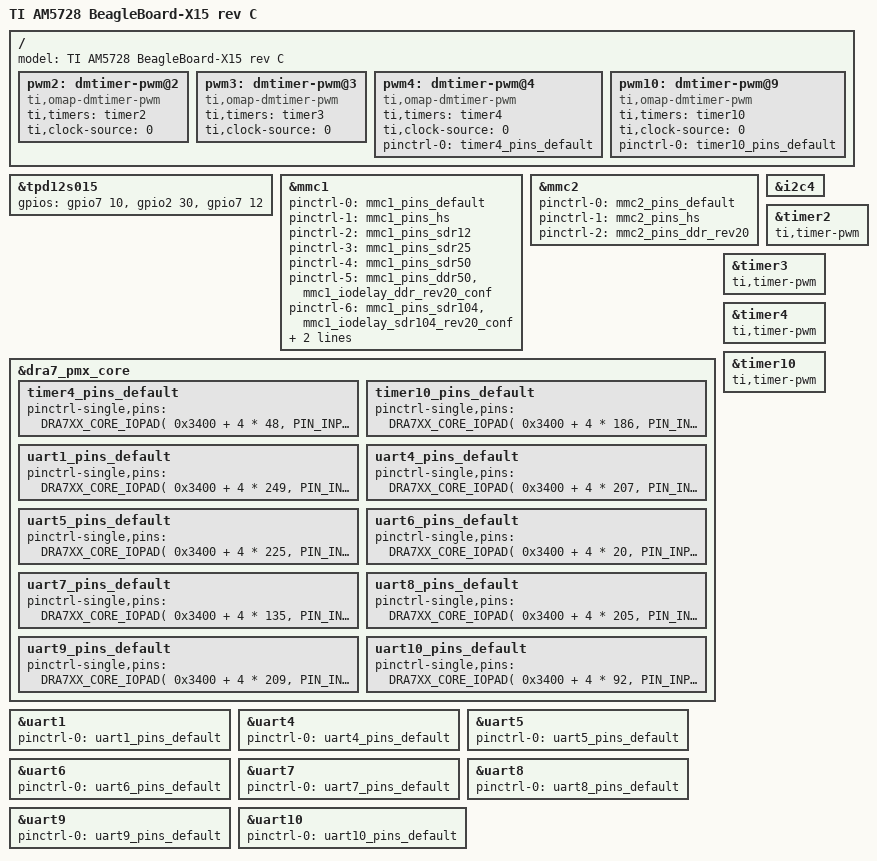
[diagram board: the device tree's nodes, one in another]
/*
 * Modify original am57xx-beagle-x15-revc.dts to allow use of
 * - I2C 4
 * - UARTs 1, 4, 5, 6, 7, 8, 9 and 10
 * - PWM (using timers 2, 3, 4 and 10)
 * and make them accessible via the bbx15 expansion headers
 *
 * Notes:
 * UARTs:
 * The debian stretch kernel only has six UARTs enabled by default, 
 * whereas this DTS enables nine (the eight above, plus existing UART3)
 * To make all of these UARTs available, change the following in the
 * kernel config and recompile the kernel:
 *   # anything >= 9 should be ok
 *   CONFIG_SERIAL_8250_NR_UARTS=12
 *   CONFIG_SERIAL_8250_RUNTIME_UARTS=12
 *
 * PWM:
 * Can be accessed via the sysfs interface (/sys/class/pwm/pwmchipx)
 * See the Kernel's Documentation/pwm.txt for details.
 */


//-----------------------------------------------------------------------------------------------------------
// original am57xx-beagle-x15-revc.dts
/*
 * Copyright (C) 2014-2017 Texas Instruments Incorporated - http://www.ti.com/
 *
 * This program is free software; you can redistribute it and/or modify
 * it under the terms of the GNU General Public License version 2 as
 * published by the Free Software Foundation.
 */

#include "am57xx-beagle-x15-common.dtsi"
#include "am57xx-cmem.dtsi"

/ {
	model = "TI AM5728 BeagleBoard-X15 rev C";

};

&tpd12s015 {
	gpios = <&gpio7 10 GPIO_ACTIVE_HIGH>,	/* gpio7_10, CT CP HPD */
		<&gpio2 30 GPIO_ACTIVE_HIGH>,	/* gpio2_30, LS OE */
		<&gpio7 12 GPIO_ACTIVE_HIGH>;	/* gpio7_12/sp1_cs2, HPD */
};

&mmc1 {
	pinctrl-names = "default", "hs", "sdr12", "sdr25", "sdr50", "ddr50", "sdr104";
	pinctrl-0 = <&mmc1_pins_default>;
	pinctrl-1 = <&mmc1_pins_hs>;
	pinctrl-2 = <&mmc1_pins_sdr12>;
	pinctrl-3 = <&mmc1_pins_sdr25>;
	pinctrl-4 = <&mmc1_pins_sdr50>;
	pinctrl-5 = <&mmc1_pins_ddr50 &mmc1_iodelay_ddr_rev20_conf>;
	pinctrl-6 = <&mmc1_pins_sdr104 &mmc1_iodelay_sdr104_rev20_conf>;
	vmmc-supply = <&vdd_3v3>;
	vqmmc-supply = <&ldo1_reg>;
};

&mmc2 {
	pinctrl-names = "default", "hs", "ddr_1_8v";
	pinctrl-0 = <&mmc2_pins_default>;
	pinctrl-1 = <&mmc2_pins_hs>;
	pinctrl-2 = <&mmc2_pins_ddr_rev20>;
};
//-----------------------------------------------------------------------------------------------------------
// end original am57xx-beagle-x15-revc.dts

/* set pinmux for extra IO */
&dra7_pmx_core {
//-----------------------------------------------------------------------------------------------------------
// pin mux for timers

  // already set by default
  //timer1_pins_default: timer1_pins_default {
  //  pinctrl-single,pins = <
  //    DRA7XX_CORE_IOPAD( 0x3400 + 4 * 162, PIN_INPUT_SLEW | MUX_MODE10 ) // E21 timer0    P17.42
  //  >;
  //}; 

  // already set by default
  //timer2_pins_default: timer2_pins_default {
  //  pinctrl-single,pins = <
  //    DRA7XX_CORE_IOPAD( 0x3400 + 4 * 163, PIN_INPUT_SLEW | MUX_MODE10 ) // F20 timer1    P17.13
  //  >;
  //}; 
		
  // already set by default
  //timer3_pins_default: timer3_pins_default {
  //  pinctrl-single,pins = <
  //    DRA7XX_CORE_IOPAD( 0x3400 + 4 * 164, PIN_INPUT_SLEW | MUX_MODE10 ) // F21 timer2    P17.12
  //  >;
  //}; 
		
  timer4_pins_default: timer4_pins_default {
    pinctrl-single,pins = <
      DRA7XX_CORE_IOPAD( 0x3400 + 4 * 48, PIN_INPUT_SLEW | MUX_MODE7 ) // P07 timer3        P16.35
    >;
  }; 

  timer10_pins_default: timer10_pins_default {
    pinctrl-single,pins = <
      DRA7XX_CORE_IOPAD( 0x3400 + 4 * 186, PIN_INPUT_SLEW | MUX_MODE10 ) // A13 timer9      P17.49
    >;
  };   

//-----------------------------------------------------------------------------------------------------------		
// pin mux for I2C

  // already set by default
  //i2c4_pins_default: i2c4_pins_default {
  //  pinctrl-single,pins = <
  //    DRA7XX_CORE_IOPAD( 0x3400 + 4 * 172, PIN_INPUT_SLEW | MUX_MODE10 ) // J14 i2c 3 scl [IO]  P17.46
  //    DRA7XX_CORE_IOPAD( 0x3400 + 4 * 171, PIN_INPUT_SLEW | MUX_MODE10 ) // B14 i2c 3 sda [IO]  P17.53
  //  >;
  //}; 

//-----------------------------------------------------------------------------------------------------------
// pin mux for uarts
  
  uart1_pins_default: uart1_pins_default {
    pinctrl-single,pins = <
      DRA7XX_CORE_IOPAD( 0x3400 + 4 * 249, PIN_INPUT_SLEW | MUX_MODE0 ) // B27 uart0 rxd    P18.30
      DRA7XX_CORE_IOPAD( 0x3400 + 4 * 248, PIN_INPUT_SLEW | MUX_MODE0 ) // C26 uart0 txd    P18.60
    >;
  };  
  
  // uart 2 not available (no pins available)
  
  // uart3 already set by default
  //uart3_pins_default: uart3_pins_default {
  //	pinctrl-single,pins = <
  //    DRA7XX_CORE_IOPAD( 0x3400 + 4 * 254, PIN_INPUT_SLEW | MUX_MODE2 ) // D27 uart2 rxd  P10.4
  //    DRA7XX_CORE_IOPAD( 0x3400 + 4 * 255, PIN_INPUT_SLEW | MUX_MODE1 ) // C28 uart2 txd  P10.5
  //	>;
  //};  

  uart4_pins_default: uart4_pins_default {
		pinctrl-single,pins = <
      DRA7XX_CORE_IOPAD( 0x3400 + 4 * 207, PIN_INPUT_SLEW | MUX_MODE4 ) // G16 uart3 rxd    P17.11
      DRA7XX_CORE_IOPAD( 0x3400 + 4 * 208, PIN_INPUT_SLEW | MUX_MODE4 ) // D17 uart3 txd    P17.14
		>;
	};

  uart5_pins_default: uart5_pins_default {
		pinctrl-single,pins = <
      DRA7XX_CORE_IOPAD( 0x3400 + 4 * 225, PIN_INPUT_SLEW | MUX_MODE2 ) // AC07 uart4 rxd   P17.7
      DRA7XX_CORE_IOPAD( 0x3400 + 4 * 226, PIN_INPUT_SLEW | MUX_MODE2 ) // AC06 uart4 txd   P17.36
		>;
	};   
  
  uart6_pins_default: uart6_pins_default {
    pinctrl-single,pins = <
      DRA7XX_CORE_IOPAD( 0x3400 + 4 * 20, PIN_INPUT_SLEW | MUX_MODE8 ) // P06 uart5 rxd     P16.10
      DRA7XX_CORE_IOPAD( 0x3400 + 4 * 21, PIN_INPUT_SLEW | MUX_MODE8 ) // R09 uart5 txd     P16.13
    >;
  };  
  
  uart7_pins_default: uart7_pins_default {
    pinctrl-single,pins = <
      DRA7XX_CORE_IOPAD( 0x3400 + 4 * 135, PIN_INPUT_SLEW | MUX_MODE2 ) // B07 uart6 rxd    P18.50
      DRA7XX_CORE_IOPAD( 0x3400 + 4 * 136, PIN_INPUT_SLEW | MUX_MODE2 ) // B08 uart6 txd    P18.51
    >;
  };   
  
  uart8_pins_default: uart8_pins_default {
    pinctrl-single,pins = <
      DRA7XX_CORE_IOPAD( 0x3400 + 4 * 205, PIN_INPUT_SLEW | MUX_MODE3 ) // C18 uart7 rxd    P17.43
      DRA7XX_CORE_IOPAD( 0x3400 + 4 * 206, PIN_INPUT_SLEW | MUX_MODE3 ) // A21 uart7 txd    P17.27
    >;
  };   

  uart9_pins_default: uart9_pins_default {
    pinctrl-single,pins = <
      DRA7XX_CORE_IOPAD( 0x3400 + 4 * 209, PIN_INPUT_SLEW | MUX_MODE3 ) // AA03 uart8 rxd   P17.10
      DRA7XX_CORE_IOPAD( 0x3400 + 4 * 210, PIN_INPUT_SLEW | MUX_MODE3 ) // AB09 uart8 txd   P17.9
    >;
  }; 
    
  uart10_pins_default: uart10_pins_default {
    pinctrl-single,pins = <
      DRA7XX_CORE_IOPAD( 0x3400 + 4 * 92, PIN_INPUT_SLEW | MUX_MODE8 ) // D01 uart9 rxd     P18.12
      DRA7XX_CORE_IOPAD( 0x3400 + 4 * 93, PIN_INPUT_SLEW | MUX_MODE8 ) // E02 uart9 txd     P18.42
    >;
  };
//-----------------------------------------------------------------------------------------------------------

};  // end pin-muxing

/* enable extra io */
&uart1 {
  pinctrl-names = "default";
  pinctrl-0 = <&uart1_pins_default>;  
	status = "okay";
};

&uart4 {
  pinctrl-names = "default";
  pinctrl-0 = <&uart4_pins_default>;    
	status = "okay";
};

&uart5 {
  pinctrl-names = "default";
  pinctrl-0 = <&uart5_pins_default>;  
	status = "okay";
};

&uart6 {
  pinctrl-names = "default";
  pinctrl-0 = <&uart6_pins_default>;    
	status = "okay";
};

&uart7 {
  pinctrl-names = "default";
  pinctrl-0 = <&uart7_pins_default>;    
	status = "okay";
};

&uart8 {
  pinctrl-names = "default";
  pinctrl-0 = <&uart8_pins_default>;    
	status = "okay";
};

&uart9 {
  pinctrl-names = "default";
  pinctrl-0 = <&uart9_pins_default>;  
	status = "okay";
};

&uart10 {
  pinctrl-names = "default";
  pinctrl-0 = <&uart10_pins_default>;  
	status = "okay";
};

&i2c4 {
  status = "okay";
};

&timer2 {
  ti,timer-pwm;
};

&timer3 {
  ti,timer-pwm;
};

&timer4 {
  ti,timer-pwm;
};

&timer10 {
  ti,timer-pwm;
};

/ {
  pwm2: dmtimer-pwm@2 {
    compatible = "ti,omap-dmtimer-pwm";
    ti,timers = <&timer2>;
    ti,clock-source = <0>;
    #pwm-cells = <3>;
  };

  pwm3: dmtimer-pwm@3 {
    compatible = "ti,omap-dmtimer-pwm";
    ti,timers = <&timer3>;
    ti,clock-source = <0>;
    #pwm-cells = <3>;
  };

  pwm4: dmtimer-pwm@4 {
    compatible = "ti,omap-dmtimer-pwm";
    ti,timers = <&timer4>;
    ti,clock-source = <0>;
    #pwm-cells = <3>;
    pinctrl-names = "default";
    pinctrl-0 = <&timer4_pins_default>;
  };  

  pwm10: dmtimer-pwm@9 {
    compatible = "ti,omap-dmtimer-pwm";
    ti,timers = <&timer10>;
    ti,clock-source = <0>;
    #pwm-cells = <3>;
    pinctrl-names = "default";
    pinctrl-0 = <&timer10_pins_default>;
  };    
};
